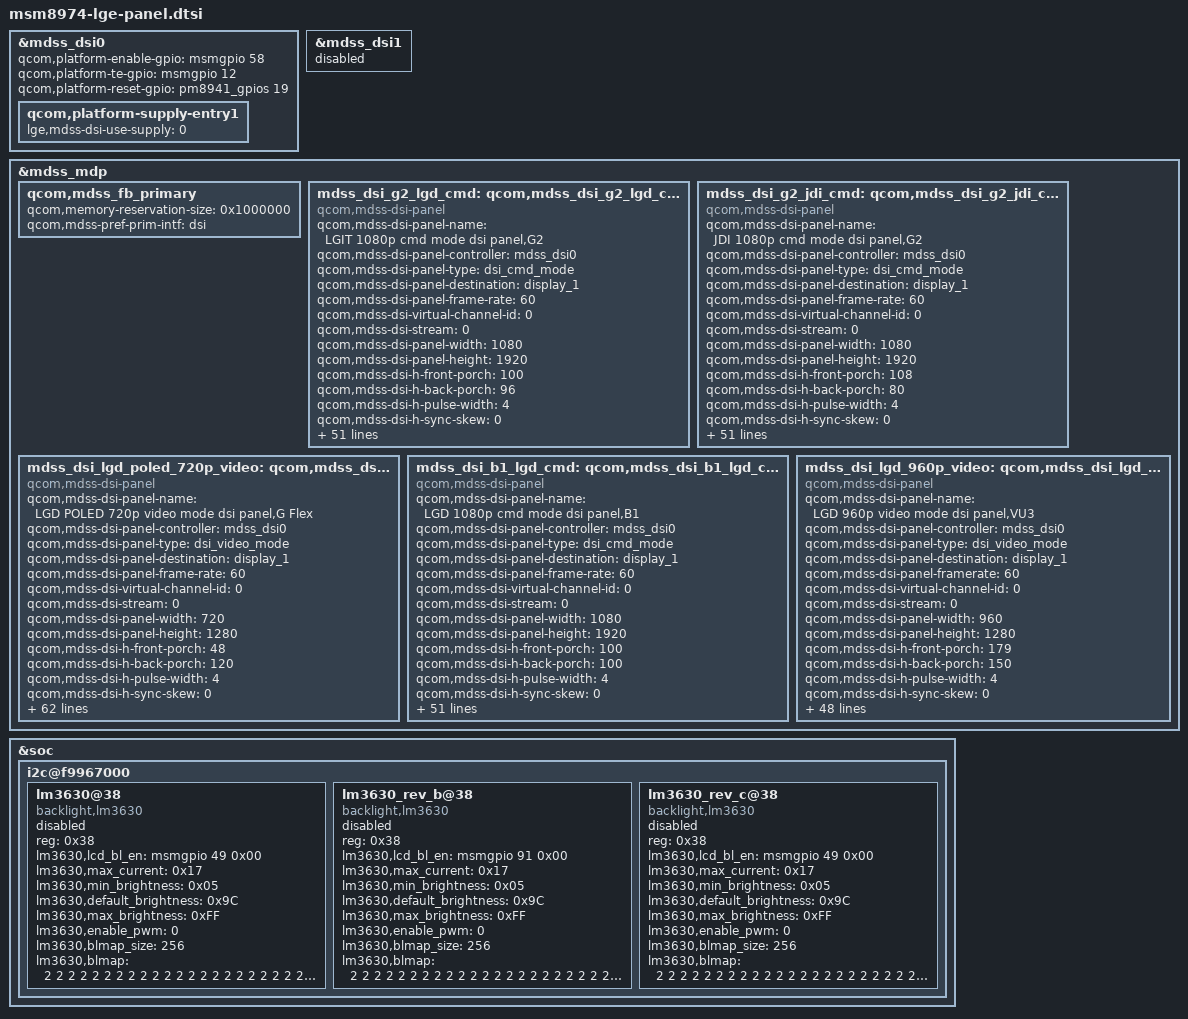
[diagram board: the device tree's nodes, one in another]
/* Copyright (c) 2013, LGE Electronics. All rights reserved.
 *
 * This program is free software; you can redistribute it and/or modify
 * it under the terms of the GNU General Public License version 2 and
 * only version 2 as published by the Free Software Foundation.
 *
 * This program is distributed in the hope that it will be useful,
 * but WITHOUT ANY WARRANTY; without even the implied warranty of
 * MERCHANTABILITY or FITNESS FOR A PARTICULAR PURPOSE.  See the
 * GNU General Public License for more details.
 */

/*---------------------------------------------------------------------------
 * This file is autogenerated file using gcdb parser. Please do not edit it.
 * Update input XML file to add a new entry or update variable in this file
 * VERSION = "1.0"
 *---------------------------------------------------------------------------*/

&mdss_dsi0 {
	qcom,platform-enable-gpio = <&msmgpio 58 0>;
	qcom,platform-te-gpio = <&msmgpio 12 0>;
	qcom,platform-reset-gpio = <&pm8941_gpios 19 0>;
	qcom,platform-supply-entry1 {
		lge,mdss-dsi-use-supply = <0>;
	};
};

&mdss_dsi1 {
	status = "disable";
};

&mdss_mdp {
		qcom,mdss_fb_primary {
			qcom,memory-reservation-size = <0x1000000>;
			qcom,mdss-pref-prim-intf = "dsi";
		};

mdss_dsi_g2_lgd_cmd: qcom,mdss_dsi_g2_lgd_cmd {
		compatible = "qcom,mdss-dsi-panel";
		qcom,mdss-dsi-panel-name = "LGIT 1080p cmd mode dsi panel,G2";
		qcom,mdss-dsi-panel-controller = <&mdss_dsi0>;
		qcom,mdss-dsi-panel-type = "dsi_cmd_mode";
		qcom,mdss-dsi-panel-destination = "display_1";
		qcom,mdss-dsi-panel-frame-rate = <60>;
		qcom,mdss-dsi-virtual-channel-id = <0>;
		qcom,mdss-dsi-stream = <0>;
		qcom,mdss-dsi-panel-width = <1080>;
		qcom,mdss-dsi-panel-height = <1920>;
		qcom,mdss-dsi-h-front-porch = <100>;
		qcom,mdss-dsi-h-back-porch = <96>;
		qcom,mdss-dsi-h-pulse-width = <4>;
		qcom,mdss-dsi-h-sync-skew = <0>;
		qcom,mdss-dsi-v-back-porch = <9>;
		qcom,mdss-dsi-v-front-porch = <10>;
		qcom,mdss-dsi-v-pulse-width = <1>;
		qcom,mdss-dsi-h-left-border = <0>;
		qcom,mdss-dsi-h-right-border = <0>;
		qcom,mdss-dsi-v-top-border = <0>;
		qcom,mdss-dsi-v-bottom-border = <0>;
		qcom,mdss-dsi-bpp = <24>;
		qcom,mdss-dsi-color-order = "rgb_swap_rgb";
		qcom,mdss-dsi-underflow-clr = <0xff>;
		qcom,mdss-dsi-border-color = <0>;
		qcom,mdss-dsi-reset-sequence = <1 5>;

		qcom,mdss-dsi-on-command = [
			29 01 00 00 00 00 02 b0 04
			05 01 00 00 00 00 01 00
			05 01 00 00 00 00 01 00
			29 01 00 00 00 00 07 b3
			04 00 00 00 00 00
			29 01 00 00 00 00 03 b6
			3a d3
			29 01 00 00 00 00 23 c1
			84 60 10 eb ff
			6f ce ff ff 17
			12 58 73 ae 31
			20 c6 ff ff 1f
			f3 ff 5f 10 10
			10 10 00 02 01
			22 22 00 01
			29 01 00 00 00 00 08 c2
			31 f7 80 0a 08
			00 00
			29 01 00 00 00 00 04 c3
			01 00 00
			29 01 00 00 00 00 17 c4
			70 00 00 00 74
			00 00 34 22 0c
			06 00 00 00 00
			74 00 00 34 22
			0c 06
			29 01 00 00 00 00 29 c6
			79 00 69 00 69
			00 00 00 00 00
			00 00 00 00 00
			00 10 16 0a 00
			79 00 69 00 69
			00 00 00 00 00
			00 00 00 00 00
			00 00 10 16 0a
			29 01 00 00 00 00 0a cb
			31 fc 3f 8c 00
			00 00 00 c0
			29 01 00 00 00 00 1f c7
			01 15 1d 27 34
			43 4d 5b 3f 48
			54 60 6c 72 7f
			01 15 1d 27 34
			43 4d 5b 3f 48
			54 60 6c 72 7f
			29 01 00 00 00 00 14 c8
			00 00 00 00 00
			fc 00 00 00 00
			00 fc 00 00 00
			00 00 fc 00
			29 01 00 00 00 00 02 cc
			0b
			29 01 00 00 00 00 0b d0
			cc 81 bb 19 99
			4c 19 19 04 00
			29 01 00 00 00 00 1a d3
			1b 33 bb bb b3
			33 33 33 00 01
			00 a0 d8 a0 00
			63 63 44 3b 37
			72 07 3d bf 77
			29 01 00 00 00 00 08 d5
			06 00 00 01 45
			01 45
			29 01 00 00 00 00 08 d5
			06 00 00 01 45
			01 45
			29 01 00 00 00 00 02 d6
			01
			29 01 00 00 00 00 03 dd
			01 95
			39 01 00 00 00 00 02 51
			ff
			15 01 00 00 00 00 02 53
			2c
			15 01 00 00 00 00 02 55
			01
			39 01 00 00 00 00 02 5e
			00
			29 01 00 00 00 00 07 b8
			07 90 1e 00 40 32
			29 01 00 00 00 00 07 b9
			07 8c 3c 20 2d 87
			29 01 00 00 00 00 07 ba
			07 8c 3c 20 2d 87
			29 01 00 00 00 00 18 ce
			75 40 43 49 55
			62 71 82 94 a8
			b9 cb db e9 f5
			fc ff 02 00 04
			04 44 20
			29 01 00 00 00 00 21 ca
			01 70 8e a0 b0
			b0 c0 85 08 3f
			10 78 08 38 08
			3f 08 90 0c 0c
			0a 06 04 04 00
			c0 10 10 3f 3f
			3f 3f
			05 01 00 00 00 00 01 29
			05 01 00 00 64 00 01 11];

		qcom,mdss-dsi-off-command = [
			29 01 00 00 00 00 08 d5
			06 00 00 00 48
			00 48
			29 01 00 00 0d 00 08 d5
			06 00 00 00 48
			00 48
			05 01 00 00 14 00 01 28
			05 01 00 00 64 00 01 10];

		qcom,mdss-dsi-on-command-state = "dsi_lp_mode";
		qcom,mdss-dsi-off-command-state = "dsi_hs_mode";
		qcom,mdss-dsi-h-sync-pulse = <0>;
		qcom,mdss-dsi-traffic-mode = "non_burst_sync_event";
		qcom,mdss-dsi-lane-map = "lane_map_0123";
		qcom,mdss-dsi-bllp-eof-power-mode;
		qcom,mdss-dsi-bllp-power-mode;
		qcom,mdss-dsi-lane-0-state;
		qcom,mdss-dsi-lane-1-state;
		qcom,mdss-dsi-lane-2-state;
		qcom,mdss-dsi-lane-3-state;
		qcom,mdss-dsi-te-pin-select = <1>;
		qcom,mdss-dsi-te-v-sync-continue-lines = <0x3c>;
		qcom,mdss-dsi-te-v-sync-rd-ptr-irq-line = <0x2c>;
		qcom,mdss-dsi-te-dcs-command = <1>;
		qcom,mdss-dsi-te-check-enable;
		qcom,mdss-dsi-te-using-te-pin;
		qcom,mdss-dsi-panel-timings = [
			c4 38 3a 32 5f 5a 39
			39 5a 03 04 00];
		qcom,mdss-dsi-t-clk-post = <0x1e>;
		qcom,mdss-dsi-t-clk-pre = <0x37>;
		qcom,mdss-dsi-bl-min-level = <1>;
		qcom,mdss-dsi-bl-max-level = <255>;
		qcom,mdss-dsi-dma-trigger = "trigger_sw";
		qcom,mdss-dsi-mdp-trigger = "none";
		qcom,mdss-dsi-bl-pmic-control-type = "bl_ctrl_wled";
		qcom,off-cmds-dsi-state = "dsi_hs_mode";
		qcom,panel-ief-off-cmds = [
			29 01 00 00 00 00 02 b0 04
			29 01 00 00 00 00 03 dd
			11 17
			39 01 00 00 00 00 02 51
			ff
			15 01 00 00 00 00 02 53
			2c
			15 01 00 00 00 00 02 55
			01
			39 01 00 00 00 00 02 5e
			00
			29 01 00 00 00 00 07 b8
			07 90 1e 00 40 32
			29 01 00 00 00 00 07 b9
			07 8c 3c 20 2d 87
			29 01 00 00 00 00 07 ba
			07 8c 3c 20 2d 87
			29 01 00 00 00 00 18 ce
			75 40 43 49 55
			62 71 82 94 a8
			b9 cb db e9 f5
			fc ff 02 00 04
			04 44 20
			29 01 00 00 00 00 21 ca
			01 70 8e a0 b0
			b0 c0 85 08 3f
			10 78 08 38 08
			3f 08 90 0c 0c
			0a 06 04 04 00
			c0 10 10 3f 3f
			3f 3f
			29 01 00 00 00 00 02 b0 03
			];
		qcom,ief-off-dsi-state = "dsi_hs_mode";
		qcom,panel-ief-on-cmds = [
			29 01 00 00 00 00 02 b0 04
			29 01 00 00 00 00 03 dd
			01 95
			39 01 00 00 00 00 02 51
			ff
			15 01 00 00 00 00 02 53
			2c
			15 01 00 00 00 00 02 55
			01
			39 01 00 00 00 00 02 5e
			00
			29 01 00 00 00 00 07 b8
			07 90 1e 00 40 32
			29 01 00 00 00 00 07 b9
			07 8c 3c 20 2d 87
			29 01 00 00 00 00 07 ba
			07 8c 3c 20 2d 87
			29 01 00 00 00 00 18 ce
			75 40 43 49 55
			62 71 82 94 a8
			b9 cb db e9 f5
			fc ff 02 00 04
			04 44 20
			29 01 00 00 00 00 21 ca
			01 70 8e a0 b0
			b0 c0 85 08 3f
			10 78 08 38 08
			3f 08 90 0c 0c
			0a 06 04 04 00
			c0 10 10 3f 3f
			3f 3f
			29 01 00 00 00 00 02 b0 03];
		qcom,ief-on-dsi-state = "dsi_hs_mode";

	};

mdss_dsi_g2_jdi_cmd: qcom,mdss_dsi_g2_jdi_cmd {
		compatible = "qcom,mdss-dsi-panel";
		qcom,mdss-dsi-panel-name = "JDI 1080p cmd mode dsi panel,G2";
		qcom,mdss-dsi-panel-controller = <&mdss_dsi0>;
		qcom,mdss-dsi-panel-type = "dsi_cmd_mode";
		qcom,mdss-dsi-panel-destination = "display_1";
		qcom,mdss-dsi-panel-frame-rate = <60>;
		qcom,mdss-dsi-virtual-channel-id = <0>;
		qcom,mdss-dsi-stream = <0>;
		qcom,mdss-dsi-panel-width = <1080>;
		qcom,mdss-dsi-panel-height = <1920>;
		qcom,mdss-dsi-h-front-porch = <108>;
		qcom,mdss-dsi-h-back-porch = <80>;
		qcom,mdss-dsi-h-pulse-width = <4>;
		qcom,mdss-dsi-h-sync-skew = <0>;
		qcom,mdss-dsi-v-back-porch = <6>;
		qcom,mdss-dsi-v-front-porch = <8>;
		qcom,mdss-dsi-v-pulse-width = <2>;
		qcom,mdss-dsi-h-left-border = <0>;
		qcom,mdss-dsi-h-right-border = <0>;
		qcom,mdss-dsi-v-top-border = <0>;
		qcom,mdss-dsi-v-bottom-border = <0>;
		qcom,mdss-dsi-bpp = <24>;
		qcom,mdss-dsi-color-order = "rgb_swap_rgb";
		qcom,mdss-dsi-underflow-color = <0xff>;
		qcom,mdss-dsi-border-color = <0>;
		qcom,mdss-dsi-reset-sequence = <1 5>;

		qcom,mdss-dsi-on-command = [
			39 01 00 00 00 00 05 2a
			00 00 04 37
			39 01 00 00 00 00 05 2b
			00 00 07 7f
			05 01 00 00 99 00 01 11
			29 01 00 00 00 00 02 b0 04
			29 01 00 00 00 00 23 c1
			84 60 00 cf 1c 94 82
			52 ef bd f7 58 73 ae
			b1 f7 de 7b 4a 81 42
			86 78 00 00 00 00 00
			42 04 06 2a 00 01
			29 01 00 00 00 00 1f c7
			00 0a 0f 17 25
			33 3e 4e 32 3b
			48 57 61 6a 7f
			00 0a 0f 17 25
			33 3e 4e 32 3b
			48 57 61 6a 7f
			29 01 00 00 00 00 14 c8
			00 00 00 00 00
			fe 00 00 00 00
			00 e0 00 00 00
			00 00 fc 00
			15 01 00 00 14 00 02 36
			00
			15 01 00 00 00 00 02 3a
			77
			29 01 00 00 00 00 03 dd
			01 95
			39 01 00 00 00 00 02 51
			ff
			15 01 00 00 00 00 02 53
			2c
			15 01 00 00 00 00 02 55
			01
			39 01 00 00 00 00 02 5e
			00
			29 01 00 00 00 00 07 b8
			07 90 1e 00 30 32
			29 01 00 00 00 00 07 b9
			07 8c 3c 20 2d 87
			29 01 00 00 00 00 07 ba
			07 8c 3c 20 2d 87
			29 01 00 00 00 00 18 ce
			75 40 43 49 55
			62 71 82 94 a8
			b9 cb db e9 f5
			fc ff 02 00 04
			04 44 20
			29 01 00 00 00 00 21 ca
			01 70 9e 85 8c
			b0 c0 a0 08 3f
			10 80 08 38 08
			3f 08 90 0c 0c
			0a 06 04 04 00
			d0 c8 10 10 3f
			3f 3f
			29 01 00 00 00 00 02 b0 03
			05 01 00 00 00 00 01 29];

		qcom,mdss-dsi-off-command = [
			05 01 00 00 14 00 01 28
			05 01 00 00 64 00 01 10];

		qcom,mdss-dsi-on-command-state = "dsi_lp_mode";
		qcom,mdss-dsi-off-command-state = "dsi_hs_mode";
		qcom,mdss-dsi-h-sync-pulse = <0>;
		qcom,mdss-dsi-traffic-mode = "non_burst_sync_event";
		qcom,mdss-dsi-lane-map = "lane_map_0123";
		qcom,mdss-dsi-bllp-eof-power-mode;
		qcom,mdss-dsi-bllp-power-mode;
		qcom,mdss-dsi-lane-0-state;
		qcom,mdss-dsi-lane-1-state;
		qcom,mdss-dsi-lane-2-state;
		qcom,mdss-dsi-lane-3-state;
		qcom,mdss-dsi-te-pin-select = <1>;
		qcom,mdss-dsi-te-v-sync-continue-lines = <0x3c>;
		qcom,mdss-dsi-te-v-sync-rd-ptr-irq-line = <0x2c>;
		qcom,mdss-dsi-te-dcs-command = <1>;
		qcom,mdss-dsi-te-check-enable;
		qcom,mdss-dsi-te-using-te-pin;
		qcom,mdss-dsi-panel-timings = [
			c4 38 3a 32 5f 5a 39
			39 5a 03 04 00];
		qcom,mdss-dsi-t-clk-post = <0x1e>;
		qcom,mdss-dsi-t-clk-pre = <0x37>;
		qcom,mdss-dsi-bl-min-level = <1>;
		qcom,mdss-dsi-bl-max-level = <255>;
		qcom,mdss-dsi-dma-trigger = "trigger_sw";
		qcom,mdss-dsi-mdp-trigger = "none";
		qcom,mdss-dsi-bl-pmic-control-type = "bl_ctrl_wled";
		qcom,off-cmds-dsi-state = "dsi_hs_mode";
		qcom,panel-ief-off-cmds = [
			29 01 00 00 00 00 02 b0 04
			29 01 00 00 00 00 03 dd
			11 17
			39 01 00 00 00 00 02 51
			ff
			15 01 00 00 00 00 02 53
			2c
			15 01 00 00 00 00 02 55
			01
			39 01 00 00 00 00 02 5e
			00
			29 01 00 00 00 00 07 b8
			07 90 1e 00 30 32
			29 01 00 00 00 00 07 b9
			07 8c 3c 20 2d 87
			29 01 00 00 00 00 07 ba
			07 8c 3c 20 2d 87
			29 01 00 00 00 00 18 ce
			75 40 43 49 55
			62 71 82 94 a8
			b9 cb db e9 f5
			fc ff 02 00 04
			04 44 20
			29 01 00 00 00 00 21 ca
			01 70 9e 85 8c
			b0 c0 a0 08 3f
			10 80 08 38 08
			3f 08 90 0c 0c
			0a 06 04 04 00
			d0 c8 10 10 3f
			3f 3f
			29 01 00 00 00 00 02 b0 03
			];
		qcom,ief-off-dsi-state = "dsi_hs_mode";
		qcom,panel-ief-on-cmds = [
			29 01 00 00 00 00 02 b0 04
			29 01 00 00 00 00 03 dd
			01 95
			39 01 00 00 00 00 02 51
			ff
			15 01 00 00 00 00 02 53
			2c
			15 01 00 00 00 00 02 55
			01
			39 01 00 00 00 00 02 5e
			00
			29 01 00 00 00 00 07 b8
			07 90 1e 00 30 32
			29 01 00 00 00 00 07 b9
			07 8c 3c 20 2d 87
			29 01 00 00 00 00 07 ba
			07 8c 3c 20 2d 87
			29 01 00 00 00 00 18 ce
			75 40 43 49 55
			62 71 82 94 a8
			b9 cb db e9 f5
			fc ff 02 00 04
			04 44 20
			29 01 00 00 00 00 21 ca
			01 70 9e 85 8c
			b0 c0 a0 08 3f
			10 80 08 38 08
			3f 08 90 0c 0c
			0a 06 04 04 00
			d0 c8 10 10 3f
			3f 3f
			29 01 00 00 00 00 02 b0 03];
		qcom,ief-on-dsi-state = "dsi_hs_mode";
	};

mdss_dsi_lgd_poled_720p_video: qcom,mdss_dsi_lgd_poled_720p_video {
		compatible = "qcom,mdss-dsi-panel";
		qcom,mdss-dsi-panel-name = "LGD POLED 720p video mode dsi panel,G Flex";
		qcom,mdss-dsi-panel-controller = <&mdss_dsi0>;
		qcom,mdss-dsi-panel-type = "dsi_video_mode";
		qcom,mdss-dsi-panel-destination = "display_1";
		qcom,mdss-dsi-panel-frame-rate = <60>;
		qcom,mdss-dsi-virtual-channel-id = <0>;
		qcom,mdss-dsi-stream = <0>;
		qcom,mdss-dsi-panel-width = <720>;
		qcom,mdss-dsi-panel-height = <1280>;
		qcom,mdss-dsi-h-front-porch = <48>;
		qcom,mdss-dsi-h-back-porch = <120>;
		qcom,mdss-dsi-h-pulse-width = <4>;
		qcom,mdss-dsi-h-sync-skew = <0>;
		qcom,mdss-dsi-v-back-porch = <16>;
		qcom,mdss-dsi-v-front-porch = <16>;
		qcom,mdss-dsi-v-pulse-width = <8>;
		qcom,mdss-dsi-h-left-border = <0>;
		qcom,mdss-dsi-h-right-border = <0>;
		qcom,mdss-dsi-v-top-border = <0>;
		qcom,mdss-dsi-v-bottom-border = <0>;
		qcom,mdss-dsi-bpp = <24>;
		qcom,mdss-dsi-color-order = "rgb_swap_rgb";
		qcom,mdss-dsi-underflow-clr = <0xff>;
		qcom,mdss-dsi-border-color = <0>;
		qcom,mdss-dsi-reset-sequence = <1 20>;

		qcom,mdss-dsi-on-command = [
			15 01 00 00 12 00 02 B0 AC // MCS access
			05 01 00 00 37 00 02 11 00 // Sleep Out : delay 55ms
			39 01 00 00 22 00 14 ED 0F 00 00 35 6A 35 6A 3E 6A 3E 6A 00 23 2C 4F 27 6B 27 6B // timing control 7th sample
			15 01 00 00 00 00 02 51 00 // Brightness
			15 01 00 00 00 00 02 53 20 // Display Control Register
			05 01 00 00 00 00 02 29 00 // Display on
		];
		qcom,mdss-dsi-off-command = [
			39 01 00 00 20 00 07 EA 96 18 6A 96 14 A8 // Power off Seq.
			05 01 00 00 20 00 02 28 00 // Display off
			39 01 00 00 10 00 04 EF 05 11 7F // Power Control
			39 01 00 00 10 00 0B E6 E0 C2 81 33 12 49 54 34 15 04 // Step Up
			05 01 00 00 88 00 02 10 00 // Sleep In : delay 7frames
		];

		qcom,mdss-dsi-on-command-state = "dsi_lp_mode";
		qcom,mdss-dsi-off-command-state = "dsi_hs_mode";
		qcom,mdss-dsi-h-sync-pulse = <0>;

		qcom,mdss-dsi-traffic-mode = "non_burst_sync_event";

		qcom,mdss-dsi-lane-map = "lane_map_0123";
		qcom,mdss-dsi-bllp-eof-power-mode;
		qcom,mdss-dsi-bllp-power-mode;
		qcom,mdss-dsi-lane-0-state;
		qcom,mdss-dsi-lane-1-state;
		qcom,mdss-dsi-lane-2-state;
		qcom,mdss-dsi-lane-3-state;
		qcom,mdss-dsi-te-pin-select = <1>;
		qcom,mdss-dsi-te-v-sync-continue-lines = <0x3c>;
		qcom,mdss-dsi-te-v-sync-rd-ptr-irq-line = <0x2c>;
		qcom,mdss-dsi-te-dcs-command = <1>;
		qcom,mdss-dsi-te-check-enable;
		qcom,mdss-dsi-te-using-te-pin;
		qcom,mdss-dsi-panel-timings = [
			6d 24 19 00 34 2f 1e
			26 2a 03 04 00
		];
		qcom,mdss-dsi-t-clk-post = <0x1f>;
		qcom,mdss-dsi-t-clk-pre = <0x2b>;
		qcom,mdss-dsi-bl-min-level = <1>;
		qcom,mdss-dsi-bl-max-level = <255>;
		qcom,mdss-dsi-dma-trigger = "trigger_sw";
		qcom,mdss-dsi-mdp-trigger = "none";
		qcom,mdss-dsi-bl-pmic-control-type = "bl_ctrl_dcs";
		qcom,off-cmds-dsi-state = "dsi_hs_mode";

		qcom,blmap_size = <256>;
		qcom,blmap = <
			0
			// unused area(001-054)
			160 160 160 160 160 160 160 160 160 160 160 160 160 160 160
			160 160 160 160 160 160 160 160 160 160 160 160 160 160 160
			160 160 160 160 160 160 160 160 160 160 160 160 160 160 160
			160 160 160 160 160 160 160 160 160
			// used area(055-255)
			160 160 160 160 160 161 161 161 161 161 161 161 161 161 161		// 055-069
			162 162 162 162 162 162 162 162 163 163 163 163 163 164 164		// 070-084
			164 164 165 165 166 166 166 167 167 168 168 168 169 170 170		// 085-099
			171 171 172 172 173 173 173 174 175 175 176 176 177 177 178		// 100-114
			178 178 179 180 180 181 181 182 182 183 183 183 184 185 185		// 115-129
			186 186 187 187 188 188 188 189 190 190 191 191 192 192 193		// 130-144
			193 193 194 195 195 196 196 197 197 198 198 198 199 200 200		// 145-159
			201 201 202 202 203 203 203 204 205 205 206 206 207 207 208		// 160-174
			208 208 209 210 210 211 212 212 213 213 214 214 215 216 216		// 175-189
			217 218 218 219 219 220 220 221 222 222 223 224 224 225 225		// 190-204
			226 226 227 228 228 229 230 230 231 231 232 232 233 234 234		// 205-219
			235 236 236 237 237 238 238 239 240 240 241 242 242 243 243		// 220-234
			244 244 245 246 246 247 248 248 249 249 250 250 251 252 252		// 235-249
			253 253 254 254 255 255											// 250-255
		>;

		/* image tuning cmds set */
		qcom,img-tune-on-dsi-state = "dsi_hs_mode";
		// CM mode0 : Normal & Sharpness (echo 0)
		qcom,img-tune-cmds-cm0 = [
			15 01 00 00 00 00 02 55 48
		];
		// CM mode0 : Normal & Sharpness (echo 1)
		// add PLC 60% on and CACC
		qcom,img-tune-cmds-ce-cm0-plc60 = [
			15 01 00 00 00 00 02 55 79
		];
		// CM mode1 : Vivid & Sharpness (echo 2)
		qcom,img-tune-cmds-cm1 = [
			15 01 00 00 00 00 02 55 C8 // add gamma enable
		];
		// CM mode1 : Vivid & Sharpness (echo 3)
		// add PLC 60% on and CACC
		qcom,img-tune-cmds-ce-cm1-plc60 = [
			15 01 00 00 00 00 02 55 F9 // add gamma enable
		];
		// CM mode2 : Natural & Sharpness (echo 4)
		qcom,img-tune-cmds-cm2 = [
			15 01 00 00 00 00 02 55 4C
		];
		// CM mode2 : Natural & Sharpness (echo 5)
		// add PLC 60% on and CACC
		qcom,img-tune-cmds-ce-cm2-plc60 = [
			15 01 00 00 00 00 02 55 7D
		];
		qcom,img-tune-off-dsi-state = "dsi_hs_mode";
};

mdss_dsi_b1_lgd_cmd: qcom,mdss_dsi_b1_lgd_cmd {
		compatible = "qcom,mdss-dsi-panel";
		qcom,mdss-dsi-panel-name = "LGD 1080p cmd mode dsi panel,B1";
		qcom,mdss-dsi-panel-controller = <&mdss_dsi0>;
		qcom,mdss-dsi-panel-type = "dsi_cmd_mode";
		qcom,mdss-dsi-panel-destination = "display_1";
		qcom,mdss-dsi-panel-frame-rate = <60>;
		qcom,mdss-dsi-virtual-channel-id = <0>;
		qcom,mdss-dsi-stream = <0>;
		qcom,mdss-dsi-panel-width = <1080>;
		qcom,mdss-dsi-panel-height = <1920>;
		qcom,mdss-dsi-h-front-porch = <100>;
		qcom,mdss-dsi-h-back-porch = <100>;
		qcom,mdss-dsi-h-pulse-width = <4>;
		qcom,mdss-dsi-h-sync-skew = <0>;
		qcom,mdss-dsi-v-back-porch = <9>;
		qcom,mdss-dsi-v-front-porch = <3>;
		qcom,mdss-dsi-v-pulse-width = <1>;
		qcom,mdss-dsi-h-left-border = <0>;
		qcom,mdss-dsi-h-right-border = <0>;
		qcom,mdss-dsi-v-top-border = <0>;
		qcom,mdss-dsi-v-bottom-border = <0>;
		qcom,mdss-dsi-bpp = <24>;
		qcom,mdss-dsi-color-order = "rgb_swap_rgb";
		qcom,mdss-dsi-underflow-clr = <0xff>;
		qcom,mdss-dsi-border-color = <0>;
		qcom,mdss-dsi-reset-sequence = <1 1 0 1 1 10>;

		qcom,mdss-dsi-on-command-state = "dsi_lp_mode";
		qcom,mdss-dsi-off-command-state = "dsi_hs_mode";
		qcom,mdss-dsi-h-sync-pulse = <0>;
		qcom,mdss-dsi-traffic-mode = "non_burst_sync_event";
		qcom,mdss-dsi-lane-map = "lane_map_0123";
		qcom,mdss-dsi-bllp-eof-power-mode;
		qcom,mdss-dsi-bllp-power-mode;
		qcom,mdss-dsi-lane-0-state;
		qcom,mdss-dsi-lane-1-state;
		qcom,mdss-dsi-lane-2-state;
		qcom,mdss-dsi-lane-3-state;
		qcom,mdss-dsi-te-pin-select = <1>;
		qcom,mdss-dsi-te-v-sync-continue-lines = <0x3c>;
		qcom,mdss-dsi-te-v-sync-rd-ptr-irq-line = <0x2c>;
		qcom,mdss-dsi-te-dcs-command = <1>;
		qcom,mdss-dsi-te-check-enable;
		qcom,mdss-dsi-te-using-te-pin;
		qcom,mdss-dsi-bl-min-level = <1>;
		qcom,mdss-dsi-bl-max-level = <255>;
		qcom,mdss-dsi-dma-trigger = "trigger_sw";
		qcom,mdss-dsi-mdp-trigger = "none";
		qcom,mdss-dsi-bl-pmic-control-type = "bl_ctrl_wled";
		qcom,off-cmds-dsi-state = "dsi_hs_mode";
		qcom,mdss-dsi-panel-timings = [
			D1 43 3A 00 5F 57
			39 45 5D 03 04 00];
		qcom,mdss-dsi-t-clk-post = <0x1e>;
		qcom,mdss-dsi-t-clk-pre = <0x37>;

		qcom,mdss-dsi-on-command = [
		
		    /* 9_21 LGD initial code */
			
			/*#CMD2 Page 4*/

			15 01 00 00 02 00 02 FF 24 //# CMD2 Page 4 LTPS Control delay 1

			/*# CGOUT Mapping */

			15 01 00 00 00 00 02 00 0F
			15 01 00 00 00 00 02 01 00
			15 01 00 00 00 00 02 02 00
			15 01 00 00 00 00 02 03 00
			15 01 00 00 00 00 02 04 0B
			15 01 00 00 00 00 02 05 0C
			15 01 00 00 00 00 02 06 00
			15 01 00 00 00 00 02 07 00
			15 01 00 00 00 00 02 08 00
			15 01 00 00 00 00 02 09 00
			15 01 00 00 00 00 02 0A 03
			15 01 00 00 00 00 02 0B 04
			15 01 00 00 00 00 02 0C 01
			15 01 00 00 00 00 02 0D 13
			15 01 00 00 00 00 02 0E 15
			15 01 00 00 00 00 02 0F 17
			15 01 00 00 00 00 02 10 0F
			15 01 00 00 00 00 02 11 00
			15 01 00 00 00 00 02 12 00
			15 01 00 00 00 00 02 13 00
			15 01 00 00 00 00 02 14 0B
			15 01 00 00 00 00 02 15 0C
			15 01 00 00 00 00 02 16 00
			15 01 00 00 00 00 02 17 00
			15 01 00 00 00 00 02 18 00
			15 01 00 00 00 00 02 19 00
			15 01 00 00 00 00 02 1A 03
			15 01 00 00 00 00 02 1B 04
			15 01 00 00 00 00 02 1C 01
			15 01 00 00 00 00 02 1D 13
			15 01 00 00 00 00 02 1E 15
			15 01 00 00 00 00 02 1F 17

			/*# LGD Driving method (single-side driving)*/

			15 01 00 00 00 00 02 20 05 //# Start Pulse related (GVST)
			15 01 00 00 00 00 02 21 01 //# STV_RISE_SEL
			15 01 00 00 00 00 02 22 00 //# STV_FALL_SEL
			15 01 00 00 00 00 02 23 00 //# FS_REG
			15 01 00 00 00 00 02 24 00 //# FW_REG
			15 01 00 00 00 00 02 25 6D //# GVST setting for power-on sequence (pls. set to 6D)
			15 01 00 00 00 00 02 26 00 //# FS_REG_V
			15 01 00 00 00 00 02 27 00 //# FW_REG_V

			/*# GCK(GCLK1/GCLK2) GCLK Setting*/

			15 01 00 00 00 00 02 2F 02 //# GCK(GCLK1/GCLK2)

			15 01 00 00 00 00 02 30 04 //# Set H/L toogle line numbers of each GCK and GCK toogle sequence number
			15 01 00 00 00 00 02 31 49 //# Set GCK Sequence in Forward/Backward scan
			15 01 00 00 00 00 02 32 23 //# Set GCK Sequence in Forward/Backward scan
			15 01 00 00 00 00 02 33 01 //# STI_REG/SWI_REG/STI_REG_V/SWI_REG_V/GCK_VPM
			15 01 00 00 00 00 02 34 00 //# STI_REG
			15 01 00 00 00 00 02 35 69 //# SWI_REG
			15 01 00 00 00 00 02 36 00 //# GCK power-on/off sequence setting
			15 01 00 00 00 00 02 37 2D //# GCK power-on/off sequence setting
			15 01 00 00 00 00 02 38 08 //# GCK power-on/off sequence setting
			15 01 00 00 00 00 02 39 00 //# STI_REG_V
			15 01 00 00 00 00 02 3A 69 //# SWI_REG_V

			/*# UD (U2D/D2U) U2DD2U */

			15 01 00 00 00 00 02 29 58 //# UD(U2D D2U)
			15 01 00 00 00 00 02 2A 16

			/*# CTRL (APO use CTRL1) APO*/
                        15 01 00 00 00 00 02 5B 00 //# CTRL (SPO use CTRL1)
			15 01 00 00 00 00 02 5F 75
			15 01 00 00 00 00 02 63 00
			15 01 00 00 00 00 02 67 04

			/*# MUX (SERx/xSELx) */
			//#15 01 00 00 00 00 02 7A 01 //# MUX(SERx/xSELx) ==> Not used pls. remove it
			15 01 00 00 00 00 02 7B 80 //# MUX sequence setting in Display Line
			15 01 00 00 00 00 02 7C D8 //# MUX power-on/off sequencesetting
			15 01 00 00 00 00 02 7D 60 //# MUX power-on/off sequencesetting
			15 01 00 00 00 00 02 7E 10 //# MUXS
			15 01 00 00 00 00 02 7F 19 //# MUXW
			15 01 00 00 00 00 02 80 00 //# SD_SHIFT_POS (MUX Rising EQ)
			15 01 00 00 00 00 02 81 06 //# MUXG1
			15 01 00 00 00 00 02 82 03 //# MUXG2
			15 01 00 00 00 00 02 83 00 //# EQT_POS (Source Rising EQ)
			15 01 00 00 00 00 02 84 03 //# SOEHT (Source OP enable Time) MUXG1+MUXG2-SOEHT>=4
			15 01 00 00 00 00 02 85 07 //# SDT_REG (Source Output Hold Time)
			15 01 00 00 00 00 02 74 10 //# MUXS_V (MUX Rising Portion)
			15 01 00 00 00 00 02 75 19 //# MUXW_V (MUX On Time)
			15 01 00 00 00 00 02 76 06 //# MUXG1_V (MUX non-overlap Time)
			15 01 00 00 00 00 02 77 03 //# MUXG2_V (MUX non-overlap Time / b wo RGB switch)

			/*# Source Control*/
			15 01 00 00 00 00 02 78 00 //# SD_SHIFT_NEG (MUX Falling EQ)
			15 01 00 00 00 00 02 79 00 //# EQ_NEG (Source Falling EQ)
			15 01 00 00 00 00 02 99 33 //# PTA/SPDUMA
			//#15 01 00 00 00 00 02 A0 33 //# PTB/SPDUMB
			15 01 00 00 00 00 02 98 00

			/*# LTPS Abnormal PWROFF Ctrl.*/
			15 01 00 00 00 00 02 B3 28
			15 01 00 00 00 00 02 B4 05
			15 01 00 00 00 00 02 B5 10

			/*# SRGB/SMX_REG/CTB/CRL*/
			//#15 01 00 00 00 00 02 9D B0 //# FWD
			15 01 00 00 00 00 02 9D B6 //# BWD

			/*# BP/FP Setting for Command Mode (BP=4 FP=4)*/
			15 01 00 00 00 00 02 93 04 //# FP
			15 01 00 00 00 00 02 94 04 //# BP

			/*# Set Inversion Type (Pixel Column)*/
			15 01 00 00 00 00 02 9B 0F //# Inversion (Column)
			15 01 00 00 00 00 02 8A 33

			/*# Less Transition Function Setting */
			15 01 00 00 00 00 02 86 1B //# Alternation
			15 01 00 00 00 00 02 87 39 //# Alternation
			15 01 00 00 00 00 02 88 1B //# Alternation
			15 01 00 00 00 00 02 89 39 //# Alternation
			15 01 00 00 00 00 02 8B F4 //# MUX_LTF (Less Transition)
			15 01 00 00 00 00 02 8C 01 //# Alternation

			/*# RTN Setting*/
			15 01 00 00 00 00 02 90 79 //# RTNA_V
			15 01 00 00 00 00 02 91 44 //# DIVB/RTNA_V/DIVA/RTNB/RTNA2/RTNA
			15 01 00 00 00 00 02 92 79 //# RTNA

			/*# CTRL PIN*/
			//#15 01 00 00 00 00 02 C4 24 //# FTE_SEL/FTE1_SEL
			//#15 01 00 00 00 00 02 C5 30 //# LEDPWM_SEL/VSOUT_SEL
			//#15 01 00 00 00 00 02 C6 00 //# HSOUT_SEL

			/*#Resolution Setting*/
			15 01 00 00 00 00 02 72 00 //#V_RES H_RES

			/*#CMD2 Page 0*/
			15 01 00 00 00 00 02 FF 20 //# Page 0 power-related setting  delay 1

			/*#A */
			15 01 00 00 00 00 02 00 01 //# Panel Type (Normally Black)
			15 01 00 00 00 00 02 01 55 //# DCA_2 / DCA_3
			15 01 00 00 00 00 02 02 45 //# DCA_4 / DCB_2
			15 01 00 00 00 00 02 03 55 //# DCB_3 / DCB_4
			15 01 00 00 00 00 02 05 50 //# VGH(2xAVDD) / VGL(AVEE-VCI1) Voltage
			15 01 00 00 00 00 02 06 9E //# VGH w/Clamping (+9V) clamp enable setting
			15 01 00 00 00 00 02 07 A8 //# VGL w/Clamping (-9V) clamp enable setting
			15 01 00 00 00 00 02 08 0C //# VCI1_regulator/VCL_regulator/VCL_chargepump/BTA3(VCI/-VCI)
			15 01 00 00 00 00 02 0B 91 //# VRHP / B9 4.7 / C3 4.8 / CD 4.9 / D7 5.0 / E1 5..1 / EB 5.2 / F0 5.25
			15 01 00 00 00 00 02 0C 91 //# VRHN / B9 4.7 / C3 4.8 / CD 4.9 / D7 5.0 / E1 5..1 / EB 5.2 / F0 5.25
			15 01 00 00 00 00 02 0E 00 //# VGHO_REG
			15 01 00 00 00 00 02 0F 00 //# VGLO_REG
			15 01 00 00 00 00 02 11 2E //# Vcom 163(-0.35V)
			15 01 00 00 00 00 02 12 20 //# VCOM level setting for BackwardC Scan
			15 01 00 00 00 00 02 13 03 //# Vcom Last Bit
			15 01 00 00 00 00 02 14 0A //# pre-regulating disable
			15 01 00 00 00 00 02 15 99 //# AVDDR +5.4V(Off)
			15 01 00 00 00 00 02 16 99 //# AVEER -5.4V(Off)

			/*# PWM Control */
			15 01 00 00 00 00 02 1B 39
			15 01 00 00 00 00 02 1C 39
			15 01 00 00 00 00 02 1D 47

			/*#Gate EQ Control*/
			15 01 00 00 00 00 02 58 05 //# GCKR_EQT1 (EQ On HighBit 8) - GCLK
			15 01 00 00 00 00 02 59 05 //# GCKR_EQT2
			15 01 00 00 00 00 02 5A 05 //# GCKF_EQT1
			15 01 00 00 00 00 02 5B 05 //# GCKF_EQT2
			15 01 00 00 00 00 02 5C 00 //# MUXR_EQT1 (1EQ On HighBit 8) - MUX
			15 01 00 00 00 00 02 5D 00 //# MUXR_EQT2 (2EQ On HighBit 8)
			15 01 00 00 00 00 02 5E 00 //# MUXF_EQT1
			15 01 00 00 00 00 02 5F 00 //# MUXF_EQT2
			15 01 00 00 00 00 02 6D 44 //# Source Bias Control

			/*#CMD2 Page 0*/
			15 01 00 00 02 00 02 FF 20 //# Page 0 power-related setting    delay 1
			15 01 00 00 02 00 02 FB 01

			/*# R+*/
			15 01 00 00 00 00 02 75 00
			15 01 00 00 00 00 02 76 00
			15 01 00 00 00 00 02 77 00
			15 01 00 00 00 00 02 78 32
			15 01 00 00 00 00 02 79 00
			15 01 00 00 00 00 02 7A 60
			15 01 00 00 00 00 02 7B 00
			15 01 00 00 00 00 02 7C 80
			15 01 00 00 00 00 02 7D 00
			15 01 00 00 00 00 02 7E 95
			15 01 00 00 00 00 02 7F 00
			15 01 00 00 00 00 02 80 AF
			15 01 00 00 00 00 02 81 00
			15 01 00 00 00 00 02 82 C4
			15 01 00 00 00 00 02 83 00
			15 01 00 00 00 00 02 84 D2
			15 01 00 00 00 00 02 85 00
			15 01 00 00 00 00 02 86 E0
			15 01 00 00 00 00 02 87 01
			15 01 00 00 00 00 02 88 0C
			15 01 00 00 00 00 02 89 01
			15 01 00 00 00 00 02 8A 2F
			15 01 00 00 00 00 02 8B 01
			15 01 00 00 00 00 02 8C 64
			15 01 00 00 00 00 02 8D 01
			15 01 00 00 00 00 02 8E 92
			15 01 00 00 00 00 02 8F 01
			15 01 00 00 00 00 02 90 D9
			15 01 00 00 00 00 02 91 02
			15 01 00 00 00 00 02 92 14
			15 01 00 00 00 00 02 93 02
			15 01 00 00 00 00 02 94 15
			15 01 00 00 00 00 02 95 02
			15 01 00 00 00 00 02 96 4A
			15 01 00 00 00 00 02 97 02
			15 01 00 00 00 00 02 98 88
			15 01 00 00 00 00 02 99 02
			15 01 00 00 00 00 02 9A B2
			15 01 00 00 00 00 02 9B 02
			15 01 00 00 00 00 02 9C EC
			15 01 00 00 00 00 02 9D 03
			15 01 00 00 00 00 02 9E 12
			15 01 00 00 00 00 02 9F 03
			15 01 00 00 00 00 02 A0 49
			15 01 00 00 00 00 02 A2 03
			15 01 00 00 00 00 02 A3 5C
			15 01 00 00 00 00 02 A4 03
			15 01 00 00 00 00 02 A5 71
			15 01 00 00 00 00 02 A6 03
			15 01 00 00 00 00 02 A7 88
			15 01 00 00 00 00 02 A9 03
			15 01 00 00 00 00 02 AA 9E
			15 01 00 00 00 00 02 AB 03
			15 01 00 00 00 00 02 AC B7
			15 01 00 00 00 00 02 AD 03
			15 01 00 00 00 00 02 AE D9
			15 01 00 00 00 00 02 AF 03
			15 01 00 00 00 00 02 B0 F5
			15 01 00 00 00 00 02 B1 03
			15 01 00 00 00 00 02 B2 FF

			/*# R-*/
			15 01 00 00 00 00 02 B3 00
			15 01 00 00 00 00 02 B4 00
			15 01 00 00 00 00 02 B5 00
			15 01 00 00 00 00 02 B6 32
			15 01 00 00 00 00 02 B7 00
			15 01 00 00 00 00 02 B8 60
			15 01 00 00 00 00 02 B9 00
			15 01 00 00 00 00 02 BA 80
			15 01 00 00 00 00 02 BB 00
			15 01 00 00 00 00 02 BC 95
			15 01 00 00 00 00 02 BD 00
			15 01 00 00 00 00 02 BE AF
			15 01 00 00 00 00 02 BF 00
			15 01 00 00 00 00 02 C0 C4
			15 01 00 00 00 00 02 C1 00
			15 01 00 00 00 00 02 C2 D2
			15 01 00 00 00 00 02 C3 00
			15 01 00 00 00 00 02 C4 E0
			15 01 00 00 00 00 02 C5 01
			15 01 00 00 00 00 02 C6 0C
			15 01 00 00 00 00 02 C7 01
			15 01 00 00 00 00 02 C8 2F
			15 01 00 00 00 00 02 C9 01
			15 01 00 00 00 00 02 CA 64
			15 01 00 00 00 00 02 CB 01
			15 01 00 00 00 00 02 CC 92
			15 01 00 00 00 00 02 CD 01
			15 01 00 00 00 00 02 CE D9
			15 01 00 00 00 00 02 CF 02
			15 01 00 00 00 00 02 D0 14
			15 01 00 00 00 00 02 D1 02
			15 01 00 00 00 00 02 D2 15
			15 01 00 00 00 00 02 D3 02
			15 01 00 00 00 00 02 D4 4A
			15 01 00 00 00 00 02 D5 02
			15 01 00 00 00 00 02 D6 88
			15 01 00 00 00 00 02 D7 02
			15 01 00 00 00 00 02 D8 B2
			15 01 00 00 00 00 02 D9 02
			15 01 00 00 00 00 02 DA EC
			15 01 00 00 00 00 02 DB 03
			15 01 00 00 00 00 02 DC 12
			15 01 00 00 00 00 02 DD 03
			15 01 00 00 00 00 02 DE 49
			15 01 00 00 00 00 02 DF 03
			15 01 00 00 00 00 02 E0 5C
			15 01 00 00 00 00 02 E1 03
			15 01 00 00 00 00 02 E2 71
			15 01 00 00 00 00 02 E3 03
			15 01 00 00 00 00 02 E4 88
			15 01 00 00 00 00 02 E5 03
			15 01 00 00 00 00 02 E6 9E
			15 01 00 00 00 00 02 E7 03
			15 01 00 00 00 00 02 E8 B7
			15 01 00 00 00 00 02 E9 03
			15 01 00 00 00 00 02 EA D9
			15 01 00 00 00 00 02 EB 03
			15 01 00 00 00 00 02 EC F5
			15 01 00 00 00 00 02 ED 03
			15 01 00 00 00 00 02 EE FF

			/*# G+*/
			15 01 00 00 00 00 02 EF 00
			15 01 00 00 00 00 02 F0 00
			15 01 00 00 00 00 02 F1 00
			15 01 00 00 00 00 02 F2 32
			15 01 00 00 00 00 02 F3 00
			15 01 00 00 00 00 02 F4 60
			15 01 00 00 00 00 02 F5 00
			15 01 00 00 00 00 02 F6 80
			15 01 00 00 00 00 02 F7 00
			15 01 00 00 00 00 02 F8 95
			15 01 00 00 00 00 02 F9 00
			15 01 00 00 00 00 02 FA AF

			/*#CMD2 Page 0*/
			15 01 00 00 02 00 02 FF 21 //# Page 0 power-related setting   delay 1
			15 01 00 00 02 00 02 FB 01

			/*#no name 0*/
			15 01 00 00 00 00 02 00 00
			15 01 00 00 00 00 02 01 C4
			15 01 00 00 00 00 02 02 00
			15 01 00 00 00 00 02 03 D2
			15 01 00 00 00 00 02 04 00
			15 01 00 00 00 00 02 05 E0
			15 01 00 00 00 00 02 06 01
			15 01 00 00 00 00 02 07 0B
			15 01 00 00 00 00 02 08 01
			15 01 00 00 00 00 02 09 2E
			15 01 00 00 00 00 02 0A 01
			15 01 00 00 00 00 02 0B 63
			15 01 00 00 00 00 02 0C 01
			15 01 00 00 00 00 02 0D 91
			15 01 00 00 00 00 02 0E 01
			15 01 00 00 00 00 02 0F D9
			15 01 00 00 00 00 02 10 02
			15 01 00 00 00 00 02 11 14
			15 01 00 00 00 00 02 12 02
			15 01 00 00 00 00 02 13 15
			15 01 00 00 00 00 02 14 02
			15 01 00 00 00 00 02 15 4A
			15 01 00 00 00 00 02 16 02
			15 01 00 00 00 00 02 17 88
			15 01 00 00 00 00 02 18 02
			15 01 00 00 00 00 02 19 B2
			15 01 00 00 00 00 02 1A 02
			15 01 00 00 00 00 02 1B EC
			15 01 00 00 00 00 02 1C 03
			15 01 00 00 00 00 02 1D 12
			15 01 00 00 00 00 02 1E 03
			15 01 00 00 00 00 02 1F 49
			15 01 00 00 00 00 02 20 03
			15 01 00 00 00 00 02 21 5C
			15 01 00 00 00 00 02 22 03
			15 01 00 00 00 00 02 23 71
			15 01 00 00 00 00 02 24 03
			15 01 00 00 00 00 02 25 88
			15 01 00 00 00 00 02 26 03
			15 01 00 00 00 00 02 27 9E
			15 01 00 00 00 00 02 28 03
			15 01 00 00 00 00 02 29 B7
			15 01 00 00 00 00 02 2A 03
			15 01 00 00 00 00 02 2B D9
			15 01 00 00 00 00 02 2D 03
			15 01 00 00 00 00 02 2F F5
			15 01 00 00 00 00 02 30 03
			15 01 00 00 00 00 02 31 FF

			/*# G-*/
			15 01 00 00 00 00 02 32 00
			15 01 00 00 00 00 02 33 00
			15 01 00 00 00 00 02 34 00
			15 01 00 00 00 00 02 35 32
			15 01 00 00 00 00 02 36 00
			15 01 00 00 00 00 02 37 60
			15 01 00 00 00 00 02 38 00
			15 01 00 00 00 00 02 39 80
			15 01 00 00 00 00 02 3A 00
			15 01 00 00 00 00 02 3B 95
			15 01 00 00 00 00 02 3D 00
			15 01 00 00 00 00 02 3F AF
			15 01 00 00 00 00 02 40 00
			15 01 00 00 00 00 02 41 C4
			15 01 00 00 00 00 02 42 00
			15 01 00 00 00 00 02 43 D2
			15 01 00 00 00 00 02 44 00
			15 01 00 00 00 00 02 45 E0
			15 01 00 00 00 00 02 46 01
			15 01 00 00 00 00 02 47 0B
			15 01 00 00 00 00 02 48 01
			15 01 00 00 00 00 02 49 2E
			15 01 00 00 00 00 02 4A 01
			15 01 00 00 00 00 02 4B 63
			15 01 00 00 00 00 02 4C 01
			15 01 00 00 00 00 02 4D 91
			15 01 00 00 00 00 02 4E 01
			15 01 00 00 00 00 02 4F D9
			15 01 00 00 00 00 02 50 02
			15 01 00 00 00 00 02 51 14
			15 01 00 00 00 00 02 52 02
			15 01 00 00 00 00 02 53 15
			15 01 00 00 00 00 02 54 02
			15 01 00 00 00 00 02 55 4A
			15 01 00 00 00 00 02 56 02
			15 01 00 00 00 00 02 58 88
			15 01 00 00 00 00 02 59 02
			15 01 00 00 00 00 02 5A B2
			15 01 00 00 00 00 02 5B 02
			15 01 00 00 00 00 02 5C EC
			15 01 00 00 00 00 02 5D 03
			15 01 00 00 00 00 02 5E 12
			15 01 00 00 00 00 02 5F 03
			15 01 00 00 00 00 02 60 49
			15 01 00 00 00 00 02 61 03
			15 01 00 00 00 00 02 62 5C
			15 01 00 00 00 00 02 63 03
			15 01 00 00 00 00 02 64 71
			15 01 00 00 00 00 02 65 03
			15 01 00 00 00 00 02 66 88
			15 01 00 00 00 00 02 67 03
			15 01 00 00 00 00 02 68 9E
			15 01 00 00 00 00 02 69 03
			15 01 00 00 00 00 02 6A B7
			15 01 00 00 00 00 02 6B 03
			15 01 00 00 00 00 02 6C D9
			15 01 00 00 00 00 02 6D 03
			15 01 00 00 00 00 02 6E F5
			15 01 00 00 00 00 02 6F 03
			15 01 00 00 00 00 02 70 FF

			/*# B+*/
			15 01 00 00 00 00 02 71 00
			15 01 00 00 00 00 02 72 00
			15 01 00 00 00 00 02 73 00
			15 01 00 00 00 00 02 74 27
			15 01 00 00 00 00 02 75 00
			15 01 00 00 00 00 02 76 4E
			15 01 00 00 00 00 02 77 00
			15 01 00 00 00 00 02 78 76
			15 01 00 00 00 00 02 79 00
			15 01 00 00 00 00 02 7A 95
			15 01 00 00 00 00 02 7B 00
			15 01 00 00 00 00 02 7C AF
			15 01 00 00 00 00 02 7D 00
			15 01 00 00 00 00 02 7E C1
			15 01 00 00 00 00 02 7F 00
			15 01 00 00 00 00 02 80 CA
			15 01 00 00 00 00 02 81 00
			15 01 00 00 00 00 02 82 DB
			15 01 00 00 00 00 02 83 01
			15 01 00 00 00 00 02 84 04
			15 01 00 00 00 00 02 85 01
			15 01 00 00 00 00 02 86 24
			15 01 00 00 00 00 02 87 01
			15 01 00 00 00 00 02 88 5E
			15 01 00 00 00 00 02 89 01
			15 01 00 00 00 00 02 8A 8A
			15 01 00 00 00 00 02 8B 01
			15 01 00 00 00 00 02 8C D0
			15 01 00 00 00 00 02 8D 02
			15 01 00 00 00 00 02 8E 0A
			15 01 00 00 00 00 02 8F 02
			15 01 00 00 00 00 02 90 0C
			15 01 00 00 00 00 02 91 02
			15 01 00 00 00 00 02 92 41
			15 01 00 00 00 00 02 93 02
			15 01 00 00 00 00 02 94 80
			15 01 00 00 00 00 02 95 02
			15 01 00 00 00 00 02 96 AB
			15 01 00 00 00 00 02 97 02
			15 01 00 00 00 00 02 98 E9
			15 01 00 00 00 00 02 99 03
			15 01 00 00 00 00 02 9A 14
			15 01 00 00 00 00 02 9B 03
			15 01 00 00 00 00 02 9C 49
			15 01 00 00 00 00 02 9D 03
			15 01 00 00 00 00 02 9E 5C
			15 01 00 00 00 00 02 9F 03
			15 01 00 00 00 00 02 A0 71
			15 01 00 00 00 00 02 A2 03
			15 01 00 00 00 00 02 A3 88
			15 01 00 00 00 00 02 A4 03
			15 01 00 00 00 00 02 A5 9E
			15 01 00 00 00 00 02 A6 03
			15 01 00 00 00 00 02 A7 B7
			15 01 00 00 00 00 02 A9 03
			15 01 00 00 00 00 02 AA D9
			15 01 00 00 00 00 02 AB 03
			15 01 00 00 00 00 02 AC F5
			15 01 00 00 00 00 02 AD 03
			15 01 00 00 00 00 02 AE FF

			/*# B-*/
			15 01 00 00 00 00 02 AF 00
			15 01 00 00 00 00 02 B0 00
			15 01 00 00 00 00 02 B1 00
			15 01 00 00 00 00 02 B2 27
			15 01 00 00 00 00 02 B3 00
			15 01 00 00 00 00 02 B4 4E
			15 01 00 00 00 00 02 B5 00
			15 01 00 00 00 00 02 B6 76
			15 01 00 00 00 00 02 B7 00
			15 01 00 00 00 00 02 B8 95
			15 01 00 00 00 00 02 B9 00
			15 01 00 00 00 00 02 BA AF
			15 01 00 00 00 00 02 BB 00
			15 01 00 00 00 00 02 BC C1
			15 01 00 00 00 00 02 BD 00
			15 01 00 00 00 00 02 BE CA
			15 01 00 00 00 00 02 BF 00
			15 01 00 00 00 00 02 C0 DB
			15 01 00 00 00 00 02 C1 01
			15 01 00 00 00 00 02 C2 04
			15 01 00 00 00 00 02 C3 01
			15 01 00 00 00 00 02 C4 24
			15 01 00 00 00 00 02 C5 01
			15 01 00 00 00 00 02 C6 5E
			15 01 00 00 00 00 02 C7 01
			15 01 00 00 00 00 02 C8 8A
			15 01 00 00 00 00 02 C9 01
			15 01 00 00 00 00 02 CA D0
			15 01 00 00 00 00 02 CB 02
			15 01 00 00 00 00 02 CC 0A
			15 01 00 00 00 00 02 CD 02
			15 01 00 00 00 00 02 CE 0C
			15 01 00 00 00 00 02 CF 02
			15 01 00 00 00 00 02 D0 41
			15 01 00 00 00 00 02 D1 02
			15 01 00 00 00 00 02 D2 80
			15 01 00 00 00 00 02 D3 02
			15 01 00 00 00 00 02 D4 AB
			15 01 00 00 00 00 02 D5 02
			15 01 00 00 00 00 02 D6 E9
			15 01 00 00 00 00 02 D7 03
			15 01 00 00 00 00 02 D8 14
			15 01 00 00 00 00 02 D9 03
			15 01 00 00 00 00 02 DA 49
			15 01 00 00 00 00 02 DB 03
			15 01 00 00 00 00 02 DC 5C
			15 01 00 00 00 00 02 DD 03
			15 01 00 00 00 00 02 DE 71
			15 01 00 00 00 00 02 DF 03
			15 01 00 00 00 00 02 E0 88
			15 01 00 00 00 00 02 E1 03
			15 01 00 00 00 00 02 E2 9E
			15 01 00 00 00 00 02 E3 03
			15 01 00 00 00 00 02 E4 B7
			15 01 00 00 00 00 02 E5 03
			15 01 00 00 00 00 02 E6 D9
			15 01 00 00 00 00 02 E7 03
			15 01 00 00 00 00 02 E8 F5
			15 01 00 00 00 00 02 E9 03
			15 01 00 00 00 00 02 EA FF

			//CMD2 Page 2
			15 01 00 00 01 00 02 FF 22 // delay 1
			15 01 00 00 00 00 02 FB 01
			
			//Image enhancement
			15 01 00 00 00 00 02 00 00
			15 01 00 00 00 00 02 01 04
			15 01 00 00 00 00 02 02 08
			15 01 00 00 00 00 02 03 0C
			15 01 00 00 00 00 02 04 10
			15 01 00 00 00 00 02 05 14
			15 01 00 00 00 00 02 06 18
			15 01 00 00 00 00 02 07 20
			15 01 00 00 00 00 02 08 24
			15 01 00 00 00 00 02 09 28
			15 01 00 00 00 00 02 0A 30
			15 01 00 00 00 00 02 0B 38
			15 01 00 00 00 00 02 0C 38
			15 01 00 00 00 00 02 0D 30
			15 01 00 00 00 00 02 0E 28
			15 01 00 00 00 00 02 0F 20
			15 01 00 00 00 00 02 10 0C
			15 01 00 00 00 00 02 11 00
			15 01 00 00 00 00 02 12 00
			15 01 00 00 00 00 02 13 00
			15 01 00 00 00 00 02 14 10
			15 01 00 00 00 00 02 15 18
			15 01 00 00 00 00 02 16 30
			15 01 00 00 00 00 02 17 18
			15 01 00 00 00 00 02 18 28
			15 01 00 00 00 00 02 19 38 
			15 01 00 00 00 00 02 1A 77
			15 01 00 00 00 00 02 1B 00
			15 01 00 00 00 00 02 1C 04
			15 01 00 00 00 00 02 1D 08
			15 01 00 00 00 00 02 1E 0C
			15 01 00 00 00 00 02 1F 10
			15 01 00 00 00 00 02 20 14
			15 01 00 00 00 00 02 21 18
			15 01 00 00 00 00 02 22 20
			15 01 00 00 00 00 02 23 18
			15 01 00 00 00 00 02 24 10
			15 01 00 00 00 00 02 25 08
			15 01 00 00 00 00 02 26 00
			15 01 00 00 00 00 02 27 00
			15 01 00 00 00 00 02 28 00
			15 01 00 00 00 00 02 29 00
			15 01 00 00 00 00 02 2A 00
			15 01 00 00 00 00 02 2B 00
			15 01 00 00 00 00 02 2F 00
			15 01 00 00 00 00 02 30 00
			15 01 00 00 00 00 02 31 00
			15 01 00 00 00 00 02 32 0A
			15 01 00 00 00 00 02 33 0F
			15 01 00 00 00 00 02 34 0A
			15 01 00 00 00 00 02 35 0A
			15 01 00 00 00 00 02 36 07
			15 01 00 00 00 00 02 37 07
			15 01 00 00 00 00 02 38 07
			15 01 00 00 00 00 02 39 07
			15 01 00 00 00 00 02 3A 07
			15 01 00 00 00 00 02 3B 07
			15 01 00 00 00 00 02 3F 07
			15 01 00 00 00 00 02 40 07
			15 01 00 00 00 00 02 41 07
			15 01 00 00 00 00 02 42 07
			15 01 00 00 00 00 02 43 0A
			15 01 00 00 00 00 02 44 0A
			15 01 00 00 00 00 02 45 0A
			15 01 00 00 00 00 02 46 0A
			15 01 00 00 00 00 02 47 0A
			15 01 00 00 00 00 02 48 0A
			15 01 00 00 00 00 02 49 0A
			15 01 00 00 00 00 02 4A 0A
			15 01 00 00 00 00 02 4B 05
			15 01 00 00 00 00 02 4C 05
			15 01 00 00 00 00 02 4D 00
			15 01 00 00 00 00 02 4E 04
			15 01 00 00 00 00 02 4F 04
			15 01 00 00 00 00 02 50 01
			15 01 00 00 00 00 02 51 03
			15 01 00 00 00 00 02 52 05
			15 01 00 00 00 00 02 53 02
			15 01 00 00 00 00 02 54 00
			15 01 00 00 00 00 02 55 02
			15 01 00 00 00 00 02 56 00
			15 01 00 00 00 00 02 58 12
			15 01 00 00 00 00 02 59 0E
			15 01 00 00 00 00 02 5A 0F
			15 01 00 00 00 00 02 5B 0E
			15 01 00 00 00 00 02 5C 16
			15 01 00 00 00 00 02 5D 0E
			15 01 00 00 00 00 02 5E 14
			15 01 00 00 00 00 02 5F 12
			15 01 00 00 00 00 02 60 16
			15 01 00 00 00 00 02 61 12
			15 01 00 00 00 00 02 62 18
			15 01 00 00 00 00 02 63 12
			15 01 00 00 00 00 02 64 2F
			15 01 00 00 00 00 02 65 82
			15 01 00 00 00 00 02 66 82
			15 01 00 00 00 00 02 67 C8
			15 01 00 00 00 00 02 68 77
			15 01 00 00 00 00 02 69 02
			15 01 00 00 00 00 02 6A 00
			15 01 00 00 00 00 02 6B 00
			15 01 00 00 00 00 02 6C 00
			15 01 00 00 00 00 02 6D 00
			15 01 00 00 00 00 02 6E 00
			15 01 00 00 00 00 02 6F 00
			15 01 00 00 00 00 02 70 00
			15 01 00 00 00 00 02 71 00
			15 01 00 00 00 00 02 78 00
			15 01 00 00 00 00 02 7B 30
			15 01 00 00 00 00 02 7C 00
			15 01 00 00 00 00 02 7D 00
			
			/*#CMD1*/
			15 01 00 00 02 00 02 FF 10 // delay 1

			//# MIPI Video Mode Bypass RAM
			15 01 00 00 00 00 02 BB 10 //#Gram access RM DM

                        //# SET_ADDRESS_MODE  inversion
                        15 01 00 00 00 00 02 36 03 //Left Right flip & Up Down flip

			/*# Video Mode Porch Setting (VBPVFPHBPHFP)*/
			39 01 00 00 00 00 06 3B 03 0A 0A 0A 0A // mipi.write 39 3B 03 0A 0A 0A 0A

			/*# Backlight & CABC Setting*/
			15 01 00 00 00 00 02 51 FF //# LED PWM enable
			15 01 00 00 00 00 02 53 2C //# HBM BCTRL DDBL (when CABC On 2C)
			15 01 00 00 00 00 02 55 91 //# Image_Enhancement CABC (1-UI2-Still3-Moving)
			15 01 00 00 00 00 02 58 00 //# Scale up (qHD HD720 -> FHD)
			15 01 00 00 00 00 02 5E 00 //# CABC minimum brightness

			/*display_on*/
			05 01 00 00 64 00 01 29  // delay 100
			/*exit_sleep_mode*/
			05 01 00 00 64 00 01 11 ];  // delay 100

            		qcom,mdss-dsi-off-command = [
		    	05 01 00 00 14 00 01 28
			05 01 00 00 64 00 01 10 ];


			/* IEF  ON/OFF command */
			qcom,panel-ief-off-cmds = [
			15 01 00 00 00 00 02 55 01
			];
			qcom,ief-off-dsi-state = "dsi_hs_mode";

			qcom,panel-ief-on-cmds = [
			15 01 00 00 00 00 02 55 91
			];
			qcom,ief-on-dsi-state = "dsi_hs_mode";
			
			};


mdss_dsi_lgd_960p_video: qcom,mdss_dsi_lgd_960p_video {
        compatible = "qcom,mdss-dsi-panel";
		qcom,mdss-dsi-panel-name = "LGD 960p video mode dsi panel,VU3";
		qcom,mdss-dsi-panel-controller = <&mdss_dsi0>;
		qcom,mdss-dsi-panel-type = "dsi_video_mode";
		qcom,mdss-dsi-panel-destination = "display_1";
		qcom,mdss-dsi-panel-framerate = <60>;
		qcom,mdss-dsi-virtual-channel-id = <0>;
		qcom,mdss-dsi-stream = <0>;
		qcom,mdss-dsi-panel-width = <960>;
		qcom,mdss-dsi-panel-height = <1280>;
		qcom,mdss-dsi-h-front-porch = <179>;
		qcom,mdss-dsi-h-back-porch = <150>;
		qcom,mdss-dsi-h-pulse-width = <4>;
		qcom,mdss-dsi-h-sync-skew = <0>;
		qcom,mdss-dsi-v-back-porch = <9>;
		qcom,mdss-dsi-v-front-porch = <3>;
		qcom,mdss-dsi-v-pulse-width = <1>;
		qcom,mdss-dsi-h-left-border = <0>;
		qcom,mdss-dsi-h-right-border = <0>;
		qcom,mdss-dsi-v-top-border = <0>;
		qcom,mdss-dsi-v-bottom-border = <0>;
		qcom,mdss-dsi-bpp = <24>;
		qcom,mdss-dsi-color-order = <0>;
		qcom,mdss-dsi-underflow-color = <0xff>;
		qcom,mdss-dsi-border-color = <0>;
        qcom,mdss-dsi-reset-sequence = <1 5>;

		qcom,mdss-dsi-on-command = [ 29 01 00 00 00 00 02 b0 04
			05 01 00 00 00 00 01 00
			05 01 00 00 00 00 01 00
			29 01 00 00 00 00 07 b3
			14 00 00 00 00 00
			29 01 00 00 00 00 03 b6
			3a d3
			29 01 00 00 00 00 23 c1
			80 62 41 eb ff
			6f ce ff ff 0f
			01 58 73 ae 31
			20 06 ff ff 1f
			f3 ff 5f 10 10
			10 10 00 00 00
			22 02 02 00
			29 01 00 00 00 00 08 c2
			31 f5 00 0a 08
			00 00
			29 01 00 00 00 00 04 c3
			01 00 00
			29 01 00 00 00 00 17 c4
			70 00 00 00 00
			05 00 05 00 15
			04 00 00 00 00
			00 05 00 05 00
			15 04
			29 01 00 00 00 00 29 c6
			00 ab 00 ab 00
			ab 00 00 00 00
			00 ab 00 ab 00
			ab 1c 23 07 00
			01 00 ab 00 ab
			00 ab 00 00 00
			00 00 ab 00 ab
			00 ab 1c 23 07
			29 01 00 00 00 00 19 c7
			00 13 1a 21 2e
			46 3c 50 5f 6a
			71 76 00 13 1a
			21 2e 46 3c 50
			5f 6a 71 76
			29 01 00 00 00 00 19 c8
			0d 13 1a 21 2e
			46 3c 50 5f 6a
			71 76 0d 13 1a
			21 2e 46 3c 50
			5f 6a 71 76
			29 01 00 00 00 00 19 c9
			00 13 1a 21 2e
			46 3c 50 5f 6a
			71 76 00 13 1a
			21 2e 46 3c 50
			5f 6a 71 76
			29 01 00 00 00 00 02 cc
			09
			29 01 00 00 00 00 0f d0
			00 00 19 18 99
			99 19 01 89 00
			55 19 99 01
			29 01 00 00 00 00 1b d3
			1b 33 bb cc c4
			33 33 33 11 01
			00 a0 d8 a0 0d
			39 33 44 22 70
			02 39 03 3d bf
			33
			29 01 00 00 00 00 08 d5
			06 00 00 01 13
			01 13
			29 01 00 00 00 00 08 d5
			06 00 00 01 13
			01 13
			29 01 00 00 00 00 08 ce
			00 01 00 c1 00
			0a 3e
			39 01 00 00 00 00 03 51
			0f ff
			15 01 00 00 00 00 02 53
			24
			15 01 00 00 00 00 02 55
			02
			39 01 00 00 00 00 03 5e
			00 00
			29 01 00 00 00 00 08 b9
			00 18 18 18 9f
			1f 80
			29 01 00 00 00 00 08 ba
			00 3f 04 40 9f
			1f d7
			29 01 00 00 00 00 1a b8
			18 80 18 18 cf
			1f 00 0c 0c 6c
			0c 6c 0c 0c 12
			da 6d ff ff 10
			b3 fb ff ff ff
			29 01 00 00 00 00 21 ca
			01 70 9a 95 a2
			98 95 8f 3f 3f
			80 80 08 80 08
			3f 08 90 0c 0c
			0a 06 04 04 00
			c8 10 10 3f 3f
			3f 3f
			29 01 00 00 00 00 03 dd
			11 15
			05 01 00 00 00 00 01 29
			05 01 00 00 78 00 01 11];
		qcom,mdss-dsi-off-command = [29 01 00 00 00 00 08 d5 06 00 00 00 48 00 48
					29 01 00 00 0d 00 08 d5 06 00 00 00 48 00 48
					29 01 00 00 00 00 02 55 00
					05 01 00 00 14 00 01 28
					05 01 00 00 64 00 01 10];
		qcom,mdss-dsi-on-command-state = "dsi_lp_mode";
		qcom,mdss-dsi-off-command-state = "dsi_hs_mode";
		qcom,mdss-dsi-h-sync-pulse = <0>;
		qcom,mdss-dsi-traffic-mode = <1>;
		qcom,mdss-dsi-lane-map = <0>;
		qcom,mdss-dsi-bllp-eof-power-mode;
		qcom,mdss-dsi-bllp-power-mode;
		qcom,mdss-dsi-lane-0-state;
		qcom,mdss-dsi-lane-1-state;
		qcom,mdss-dsi-lane-2-state;
		qcom,mdss-dsi-lane-3-state;
		qcom,mdss-dsi-te-pin-select = <1>;
		qcom,mdss-dsi-te-v-sync-rd-ptr-irq-line = <0x2c>;
		qcom,mdss-dsi-te-dcs-command = <1>;
		qcom,mdss-dsi-te-check-enable;
		qcom,mdss-dsi-te-using-te-pin;
		qcom,mdss-dsi-panel-timings = [8F 2F 25 00 43 4B 2A 31 3C 03 04 00];
		qcom,mdss-dsi-t-clk-post = <0x1F>;
		qcom,mdss-dsi-t-clk-pre = <0x2F>;
		qcom,mdss-dsi-bl-min-level = <1>;
		qcom,mdss-dsi-bl-max-level = <255>;
		qcom,mdss-dsi-dma-trigger = <4>;
		qcom,mdss-dsi-mdp-trigger = <0>;
		qcom,mdss-dsi-bl-pmic-control-type = "bl_ctrl_wled";
		qcom,panel-ief-off-cmds = [
			29 01 00 00 00 00 02 b0 04
			29 01 00 00 00 00 03 dd
			11 17
			29 01 00 00 00 00 21 ca
			01 70 9a 95 a2
			95 90 8f 3f 3f
			80 80 08 80 08
			3f 08 90 0c 0c
			0a 06 04 04 00
			c8 10 10 3f 3f
			3f 3f
			29 01 00 00 00 00 02 b0 03
			];
		qcom,ief-off-dsi-state = "dsi_hs_mode";
			qcom,panel-ief-on-cmds = [
			29 01 00 00 00 00 02 b0 04
			29 01 00 00 00 00 21 ca
			01 70 9a 95 a2
			98 95 8f 3f 3f
			80 80 08 80 08
			3f 08 90 0c 0c
			0a 06 04 04 00
			c8 10 10 3f 3f
			3f 3f
			29 01 00 00 00 00 03 dd
			01 95
			29 01 00 00 00 00 02 b0 03
			];
		qcom,ief-on-dsi-state = "dsi_hs_mode";
	};
		
};

&soc {

	i2c@f9967000 {
		lm3630@38 {
			compatible = "backlight,lm3630";
			status = "disable";
			reg = <0x38>;
			lm3630,lcd_bl_en = <&msmgpio 49 0x00>;
			lm3630,max_current = <0x17>;
			lm3630,min_brightness = <0x05>;
			lm3630,default_brightness = <0x9C>;
			lm3630,max_brightness = <0xFF>;
			lm3630,enable_pwm = <0>;
			lm3630,blmap_size = <256>;
			lm3630,blmap = <
				2 2 2 2 2 2 2 2 2 2 2 2 2 2 2
				2 2 2 2 2 2 2 2 2 2 2 2 2 2 2
				2 2 2 2 2 2 2 2 3 3 3 3 3 3 3
				3 3 3 3 3 3 3 3 3 3 3 3 3 3 3
				3 3 3 3 4 4 4 4 4 4 4 4 5 5 5
				5 5 5 6 6 6 6 6 6 6 6 7 7 7 7
				8 8 8 8 9 9 10 10 11 11 11 12 12 13 13 14
				14 15 15 16 16 17 17 18 18 19 19 20 20 21 21
				22 22 23 23 24 24 25 25 26 27 27 28 28 29 30
				30 31 32 32 33 34 34 35 36 36 37 38 39 39 40
				41 42 43 43 44 45 46 47 48 49 50 51 51 52 53
				54 55 56 57 58 59 60 61 63 64 65 66 67 68 69
				70 72 73 74 75 76 78 79 80 82 83 84 85 87 88
				90 91 92 94 95 97 98 100 101 103 104 106 107 109 110
				112 114 115 117 119 120 122 124 126 127 129 131 133 134 136
				138 140 142 144 146 148 150 152 154 156 158 160 162 164 166
				168 170 173 175 177 179 181 184 186 188 191 193 195 198 200>;
		};

		lm3630_rev_b@38 {
			compatible = "backlight,lm3630";
			status = "disable";
			reg = <0x38>;
			lm3630,lcd_bl_en = <&msmgpio 91 0x00>;
			lm3630,max_current = <0x17>;
			lm3630,min_brightness = <0x05>;
			lm3630,default_brightness = <0x9C>;
			lm3630,max_brightness = <0xFF>;
			lm3630,enable_pwm = <0>;
			lm3630,blmap_size = <256>;
			lm3630,blmap = <
				2 2 2 2 2 2 2 2 2 2 2 2 2 2 2
				2 2 2 2 2 2 2 2 2 2 2 2 2 2 2
				2 2 2 2 2 2 2 2 3 3 3 3 3 3 3
				3 3 3 3 3 3 3 3 3 3 3 3 3 3 3
				3 3 3 3 4 4 4 4 4 4 4 4 5 5 5
				5 5 5 6 6 6 6 6 6 6 6 7 7 7 7
				8 8 8 8 9 9 10 10 11 11 11 12 12 13 13 14
				14 15 15 16 16 17 17 18 18 19 19 20 20 21 21
				22 22 23 23 24 24 25 25 26 27 27 28 28 29 30
				30 31 32 32 33 34 34 35 36 36 37 38 39 39 40
				41 42 43 43 44 45 46 47 48 49 50 51 51 52 53
				54 55 56 57 58 59 60 61 63 64 65 66 67 68 69
				70 72 73 74 75 76 78 79 80 82 83 84 85 87 88
				90 91 92 94 95 97 98 100 101 103 104 106 107 109 110
				112 114 115 117 119 120 122 124 126 127 129 131 133 134 136
				138 140 142 144 146 148 150 152 154 156 158 160 162 164 166
				168 170 173 175 177 179 181 184 186 188 191 193 195 198 200>;
		};

		lm3630_rev_c@38 {
			compatible = "backlight,lm3630";
			status = "disable";
			reg = <0x38>;
			lm3630,lcd_bl_en = <&msmgpio 49 0x00>;
			lm3630,max_current = <0x17>;
			lm3630,min_brightness = <0x05>;
			lm3630,default_brightness = <0x9C>;
			lm3630,max_brightness = <0xFF>;
			lm3630,enable_pwm = <0>;
			lm3630,blmap_size = <256>;
			lm3630,blmap = <
				2 2 2 2 2 2 2 2 2 2 2 2 2 2 2
				2 2 2 2 2 2 2 2 2 2 2 2 2 2 2
				2 2 2 2 2 2 2 2 3 3 3 3 3 3 3
				3 3 3 3 3 3 3 3 3 3 3 3 3 3 3
				3 3 3 3 4 4 4 4 4 4 4 4 5 5 5
				5 5 5 6 6 6 6 6 6 6 6 7 7 7 7
				8 8 8 8 9 9 10 10 11 11 11 12 12 13 13 14
				14 15 15 16 16 17 17 18 18 19 19 20 20 21 21
				22 22 23 23 24 24 25 25 26 27 27 28 28 29 30
				30 31 32 32 33 34 34 35 36 36 37 38 39 39 40
				41 42 43 43 44 45 46 47 48 49 50 51 51 52 53
				54 55 56 57 58 59 60 61 63 64 65 66 67 68 69
				70 72 73 74 75 76 78 79 80 82 83 84 85 87 88
				90 91 92 94 95 97 98 100 101 103 104 106 107 109 110
				112 114 115 117 119 120 122 124 126 127 129 131 133 134 136
				138 140 142 144 146 148 150 152 154 156 158 160 162 164 166
				168 170 173 175 177 179 181 184 186 188 191 193 195 198 200>;
		};
	};
};
